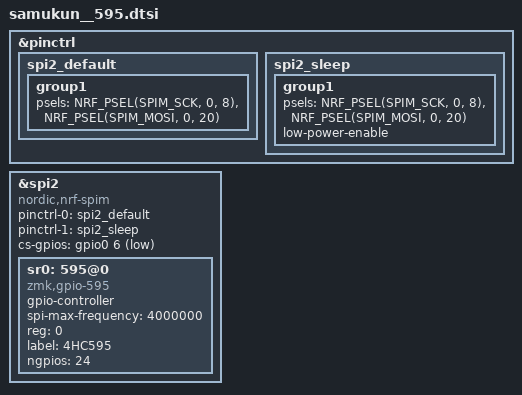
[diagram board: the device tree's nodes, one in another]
/*
 * Copyright (c) 2020 Pete Johanson
 *
 * SPDX-License-Identifier: MIT
 */

&pinctrl {
	spi2_default: spi2_default {
		group1 {
			psels = <NRF_PSEL(SPIM_SCK, 0, 8)>,
							<NRF_PSEL(SPIM_MOSI, 0, 20)>;
							// ,<NRF_PSEL(SPIM_MISO, 0, 17)>;
		};
	};
	spi2_sleep: spi2_sleep {
		group1 {
			psels = <NRF_PSEL(SPIM_SCK, 0, 8)>,
							<NRF_PSEL(SPIM_MOSI, 0, 20)>;
							// ,<NRF_PSEL(SPIM_MISO, 0, 17)>;
			low-power-enable;
		};
	};
};

// // release gpio1 12 & 13 from xiao_ble-pinctrl.dtsi
// // for &trackball { irq-gpios }
// &uart0 {
// 	status = "disabled";
// };

&spi2 {
	compatible = "nordic,nrf-spim";
	status = "okay";
	pinctrl-0 = <&spi2_default>;
	pinctrl-1 = <&spi2_sleep>;
	pinctrl-names = "default", "sleep";
	cs-gpios = <&gpio0 6 GPIO_ACTIVE_LOW>;

	sr0: 595@0 {
		compatible = "zmk,gpio-595";
		status = "okay";
		gpio-controller;
		spi-max-frequency = <4000000>;
		reg = <0>;
		label = "4HC595";
		#gpio-cells = <2>;
		ngpios = <24>;
	};

};
